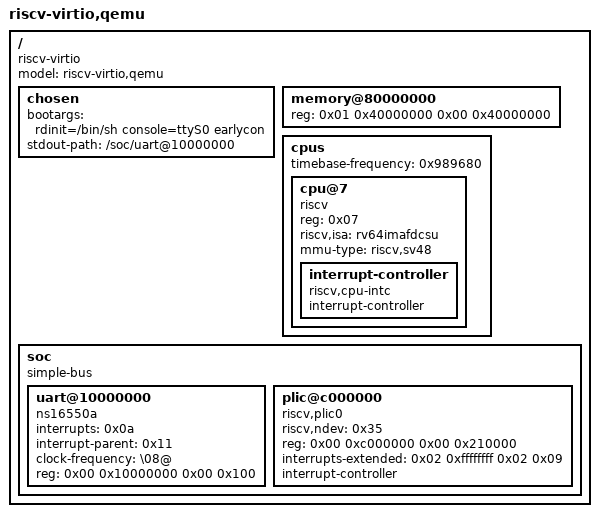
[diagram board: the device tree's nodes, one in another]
/dts-v1/;

/ {
	#address-cells = <0x02>;
	#size-cells = <0x02>;
	compatible = "riscv-virtio";
	model = "riscv-virtio,qemu";

	chosen {
		bootargs = "rdinit=/bin/sh console=ttyS0 earlycon";
		stdout-path = "/soc/uart@10000000";
	};

	memory@80000000 {
		device_type = "memory";
		reg = <0x01 0x40000000 0x00 0x40000000>;
	};

	cpus {
		#address-cells = <0x01>;
		#size-cells = <0x00>;
		timebase-frequency = <0x989680>;

		cpu@7 {
			phandle = <0x01>;
			device_type = "cpu";
			reg = <0x07>;
			status = "okay";
			compatible = "riscv";
			riscv,isa = "rv64imafdcsu";
			mmu-type = "riscv,sv48";

			interrupt-controller {
				#interrupt-cells = <0x01>;
				interrupt-controller;
				compatible = "riscv,cpu-intc";
				phandle = <0x02>;
			};
		};
	};

	soc {
		#address-cells = <0x02>;
		#size-cells = <0x02>;
		compatible = "simple-bus";
		ranges;

		uart@10000000 {
			interrupts = <0x0a>;
			interrupt-parent = <0x11>;
			clock-frequency = "\08@";
			reg = <0x00 0x10000000 0x00 0x100>;
			compatible = "ns16550a";
		};


		plic@c000000 {
			phandle = <0x11>;
			riscv,ndev = <0x35>;
			reg = <0x00 0xc000000 0x00 0x210000>;
			interrupts-extended = <0x02 0xffffffff 0x02 0x09>;
			interrupt-controller;
			compatible = "riscv,plic0";
			#interrupt-cells = <0x01>;
			#address-cells = <0x00>;
		};
	};
};
